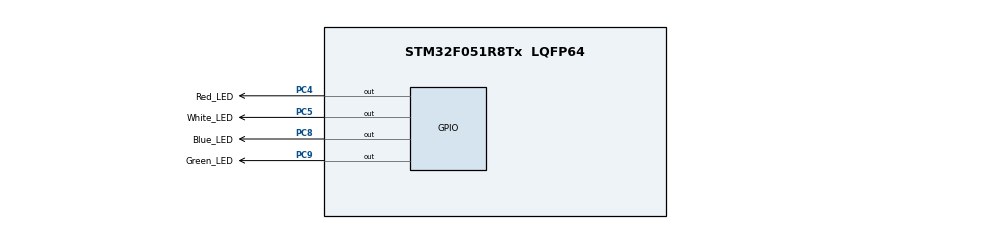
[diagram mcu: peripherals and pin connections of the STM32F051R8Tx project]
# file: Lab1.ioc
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Mcu.Family=STM32F0
Mcu.Name=STM32F051R8Tx
Mcu.Package=LQFP64
PC4.GPIO_Label=Red_LED
PC4.Signal=GPIO_Output
PC5.GPIO_Label=White_LED
PC5.Signal=GPIO_Output
PC8.GPIO_Label=Blue_LED
PC8.Signal=GPIO_Output
PC9.GPIO_Label=Green_LED
PC9.Signal=GPIO_Output
ProjectManager.HeapSize=0x200
ProjectManager.StackSize=0x400
ProjectManager.TargetToolchain=STM32CubeIDE
board=custom

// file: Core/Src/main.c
/* USER CODE BEGIN Header */
/**
  ******************************************************************************
  * @file           : main.c
  * @brief          : Main program body
  ******************************************************************************
  * @attention
  *
  * Copyright (c) 2025 STMicroelectronics.
  * All rights reserved.
  *
  * This software is licensed under terms that can be found in the LICENSE file
  * in the root directory of this software component.
  * If no LICENSE file comes with this software, it is provided AS-IS.
  *
  ******************************************************************************
  */
/* USER CODE END Header */
#include "main.h"

/* USER CODE BEGIN PD */
// BLINKING FREQUENCY
#define GREEN_LED_FREQ 1 // 1 Hz
#define BLUE_LED_FREQ 0.5 // 0.5 Hz
#define RED_LED_FREQ 0.7 // 0.7 Hz
#define WHITE_LED_FREQ 1.5 // 1.5 Hz

// LED NAMES
#define GREEN GPIO_PIN_9
#define BLUE GPIO_PIN_8
#define RED GPIO_PIN_4
#define WHITE GPIO_PIN_5
/* USER CODE END PD */

/* USER CODE BEGIN PM */
#define FREQ_TO_MS(x) (1000.0 / (2*(x)))
/* USER CODE END PM */

void SystemClock_Config(void);
static void MX_GPIO_Init(void);

int main(void)
{

  /* USER CODE BEGIN 1 */
	uint32_t last_green_ms = 0;
	uint32_t last_blue_ms = 0;
	uint32_t last_red_ms = 0;
	uint32_t last_white_ms = 0;
  /* USER CODE END 1 */

  /* MCU Configuration--------------------------------------------------------*/

  /* Reset of all peripherals, Initializes the Flash interface and the Systick. */
  HAL_Init();

  /* Configure the system clock */
  SystemClock_Config();

  /* Initialize all configured peripherals */
  MX_GPIO_Init();

  /* Infinite loop */
  while (1)
  {

	  //	SIMPLE BLINKING

	  /* HAL_GPIO_WritePin(GPIOC, GPIO_PIN_4 | GPIO_PIN_5 | GPIO_PIN_8 | GPIO_PIN_9, GPIO_PIN_SET);
	  HAL_Delay(500);
	  HAL_GPIO_WritePin(GPIOC, GPIO_PIN_4 | GPIO_PIN_5 | GPIO_PIN_8 | GPIO_PIN_9, GPIO_PIN_RESET);
	  HAL_Delay(500); */

	  //	BEAUTIFUL BLINKING
	  uint32_t now_ms = HAL_GetTick();

	  if (now_ms - last_green_ms >= FREQ_TO_MS(GREEN_LED_FREQ)){
		  HAL_GPIO_TogglePin(GPIOC, GREEN);
		  last_green_ms = now_ms;
	  }

	  if (now_ms - last_blue_ms >= FREQ_TO_MS(BLUE_LED_FREQ)){
		  HAL_GPIO_TogglePin(GPIOC, BLUE);
		  last_blue_ms = now_ms;
	  }

	  if (now_ms - last_red_ms >= FREQ_TO_MS(RED_LED_FREQ)){
		  HAL_GPIO_TogglePin(GPIOC, RED);
		  last_red_ms = now_ms;
	  }

	  if (now_ms - last_white_ms >= FREQ_TO_MS(WHITE_LED_FREQ)){
		  HAL_GPIO_TogglePin(GPIOC, WHITE);
		  last_white_ms = now_ms;
	  }
  }
}

void SystemClock_Config(void)
{
  RCC_OscInitTypeDef RCC_OscInitStruct = {0};
  RCC_ClkInitTypeDef RCC_ClkInitStruct = {0};

  /** Initializes the RCC Oscillators according to the specified parameters
  * in the RCC_OscInitTypeDef structure.
  */
  RCC_OscInitStruct.OscillatorType = RCC_OSCILLATORTYPE_HSI;
  RCC_OscInitStruct.HSIState = RCC_HSI_ON;
  RCC_OscInitStruct.HSICalibrationValue = RCC_HSICALIBRATION_DEFAULT;
  RCC_OscInitStruct.PLL.PLLState = RCC_PLL_NONE;
  if (HAL_RCC_OscConfig(&RCC_OscInitStruct) != HAL_OK)
  {
    Error_Handler();
  }

  /** Initializes the CPU, AHB and APB buses clocks
  */
  RCC_ClkInitStruct.ClockType = RCC_CLOCKTYPE_HCLK|RCC_CLOCKTYPE_SYSCLK
                              |RCC_CLOCKTYPE_PCLK1;
  RCC_ClkInitStruct.SYSCLKSource = RCC_SYSCLKSOURCE_HSI;
  RCC_ClkInitStruct.AHBCLKDivider = RCC_SYSCLK_DIV1;
  RCC_ClkInitStruct.APB1CLKDivider = RCC_HCLK_DIV1;

  if (HAL_RCC_ClockConfig(&RCC_ClkInitStruct, FLASH_LATENCY_0) != HAL_OK)
  {
    Error_Handler();
  }
}

static void MX_GPIO_Init(void)
{
  GPIO_InitTypeDef GPIO_InitStruct = {0};

  /* GPIO Ports Clock Enable */
  __HAL_RCC_GPIOC_CLK_ENABLE();

  /*Configure GPIO pin Output Level */
  HAL_GPIO_WritePin(GPIOC, Red_LED_Pin|White_LED_Pin|Blue_LED_Pin|Green_LED_Pin, GPIO_PIN_RESET);

  /*Configure GPIO pins : Red_LED_Pin White_LED_Pin Blue_LED_Pin Green_LED_Pin */
  GPIO_InitStruct.Pin = Red_LED_Pin|White_LED_Pin|Blue_LED_Pin|Green_LED_Pin;
  GPIO_InitStruct.Mode = GPIO_MODE_OUTPUT_PP;
  GPIO_InitStruct.Pull = GPIO_NOPULL;
  GPIO_InitStruct.Speed = GPIO_SPEED_FREQ_LOW;
  HAL_GPIO_Init(GPIOC, &GPIO_InitStruct);

}

void Error_Handler(void)
{
  __disable_irq();
  while (1)
  {
  }
}
